VERSION ""

NS_ :

BS_:

BU_: PanelECU
VAL_TABLE_ TransmitError 1 "Error" 0 "Right" ;
VAL_TABLE_ Receive_Error 1 "Error" 0 "Right" ;
VAL_TABLE_ ESD_Error 1 "ESD_Error" 0 "ESD_Right" ;
VAL_TABLE_ SSD_Error 1 "SSD_Error" 0 "SSD_Right" ;
VAL_TABLE_ Master_Slave 1 "Master" 0 "Slave" ;
VAL_TABLE_ Sleep_on_off 1 "Sleep_on" 0 "Sleep_off" ;
VAL_TABLE_ Power_on_off 1 "Power_on" 0 "Power_off" ;
VAL_TABLE_ Link_on_off 1 "Link_on" 0 "Link_off" ;

BO_ 3221225472 VECTOR__INDEPENDENT_SIG_MSG: 0 Vector__XXX
 SG_ CmdPhyValue : 0|8@1- (1,0) [0|0] "" Vector__XXX
 SG_ CmdAddr : 0|8@1- (1,0) [0|0] "" Vector__XXX
 SG_ CmdPhyAdr : 0|8@1- (1,0) [0|0] "" Vector__XXX
 SG_ CmdNumber : 0|8@1- (1,0) [0|0] "" Vector__XXX
 SG_ CmdNumber : 0|8@1- (1,0) [0|0] "" Vector__XXX
 SG_ CmdNumber : 0|8@1- (1,0) [0|0] "" Vector__XXX
 SG_ CmdNumber : 0|8@1- (1,0) [0|0] "" Vector__XXX
 SG_ CmdNumber : 0|8@1- (1,0) [0|0] "" Vector__XXX
 SG_ CmdNumber : 0|8@1- (1,0) [0|0] "" Vector__XXX
 SG_ CmdNumber : 0|8@1- (1,0) [0|0] "" Vector__XXX
 SG_ CmdNumber : 0|8@1- (1,0) [0|0] "" Vector__XXX
 SG_ CmdNumber : 0|8@1- (1,0) [0|0] "" Vector__XXX
 SG_ CRCErrorCount : 0|8@1- (1,0) [0|0] "" Vector__XXX
 SG_ CRCErrorCount : 0|8@1- (1,0) [0|0] "" Vector__XXX

BO_ 1040 LP_COMMAND: 8 PanelECU

BO_ 1024 LP_OPERATOR: 8 PanelECU

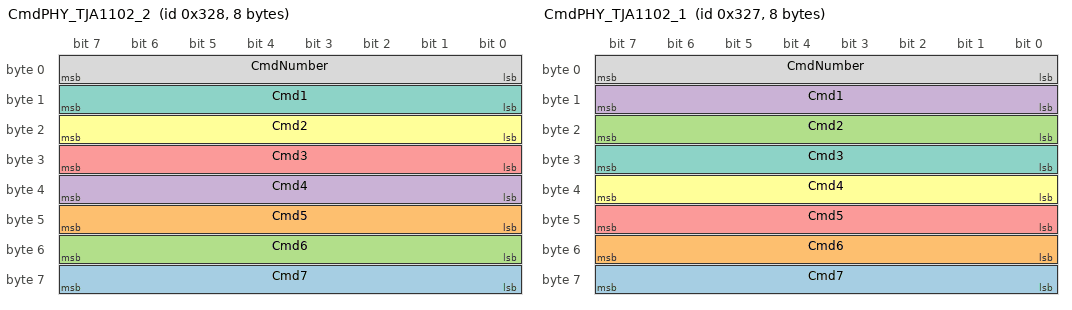
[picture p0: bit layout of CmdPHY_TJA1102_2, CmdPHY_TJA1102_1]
BO_ 808 CmdPHY_TJA1102_2: 8 PanelECU
 SG_ Cmd7 : 56|8@1- (1,0) [0|0] "" Vector__XXX
 SG_ Cmd5 : 40|8@1- (1,0) [0|0] "" Vector__XXX
 SG_ Cmd6 : 48|8@1- (1,0) [0|0] "" Vector__XXX
 SG_ Cmd4 : 32|8@1- (1,0) [0|0] "" Vector__XXX
 SG_ Cmd3 : 24|8@1- (1,0) [0|0] "" Vector__XXX
 SG_ Cmd2 : 16|8@1- (1,0) [0|0] "" Vector__XXX
 SG_ Cmd1 : 8|8@1- (1,0) [0|0] "" Vector__XXX
 SG_ CmdNumber : 0|8@1- (1,0) [0|0] "" Vector__XXX

BO_ 807 CmdPHY_TJA1102_1: 8 PanelECU
 SG_ Cmd7 : 56|8@1- (1,0) [0|0] "" Vector__XXX
 SG_ Cmd6 : 48|8@1- (1,0) [0|0] "" Vector__XXX
 SG_ Cmd2 : 16|8@1- (1,0) [0|0] "" Vector__XXX
 SG_ Cmd1 : 8|8@1- (1,0) [0|0] "" Vector__XXX
 SG_ Cmd5 : 40|8@1- (1,0) [0|0] "" Vector__XXX
 SG_ Cmd4 : 32|8@1- (1,0) [0|0] "" Vector__XXX
 SG_ Cmd3 : 24|8@1- (1,0) [0|0] "" Vector__XXX
 SG_ CmdNumber : 0|8@1- (1,0) [0|0] "" Vector__XXX

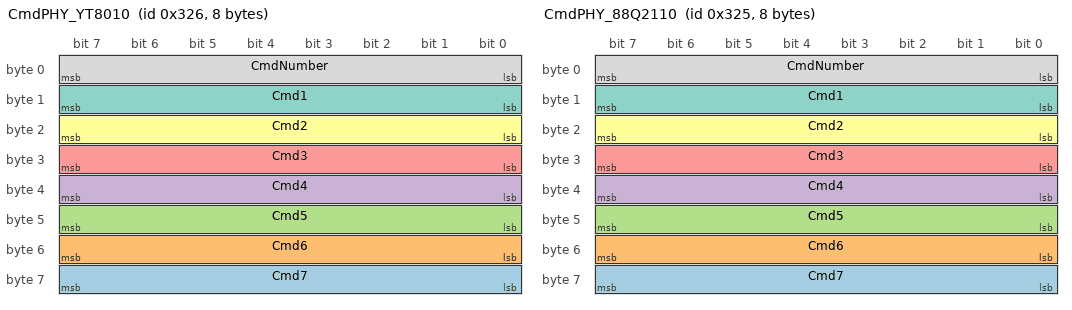
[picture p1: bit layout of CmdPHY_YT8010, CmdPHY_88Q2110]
BO_ 806 CmdPHY_YT8010: 8 PanelECU
 SG_ Cmd7 : 56|8@1- (1,0) [0|0] "" Vector__XXX
 SG_ Cmd6 : 48|8@1- (1,0) [0|0] "" Vector__XXX
 SG_ Cmd5 : 40|8@1- (1,0) [0|0] "" Vector__XXX
 SG_ Cmd4 : 32|8@1- (1,0) [0|0] "" Vector__XXX
 SG_ Cmd3 : 24|8@1- (1,0) [0|0] "" Vector__XXX
 SG_ Cmd2 : 16|8@1- (1,0) [0|0] "" Vector__XXX
 SG_ Cmd1 : 8|8@1- (1,0) [0|0] "" Vector__XXX
 SG_ CmdNumber : 0|8@1- (1,0) [0|0] "" Vector__XXX

BO_ 805 CmdPHY_88Q2110: 8 PanelECU
 SG_ Cmd7 : 56|8@1- (1,0) [0|0] "" Vector__XXX
 SG_ Cmd6 : 48|8@1- (1,0) [0|0] "" Vector__XXX
 SG_ Cmd5 : 40|8@1- (1,0) [0|0] "" Vector__XXX
 SG_ Cmd4 : 32|8@1- (1,0) [0|0] "" Vector__XXX
 SG_ Cmd3 : 24|8@1- (1,0) [0|0] "" Vector__XXX
 SG_ Cmd2 : 16|8@1- (1,0) [0|0] "" Vector__XXX
 SG_ Cmd1 : 8|8@1- (1,0) [0|0] "" Vector__XXX
 SG_ CmdNumber : 0|8@1- (1,0) [0|0] "" Vector__XXX

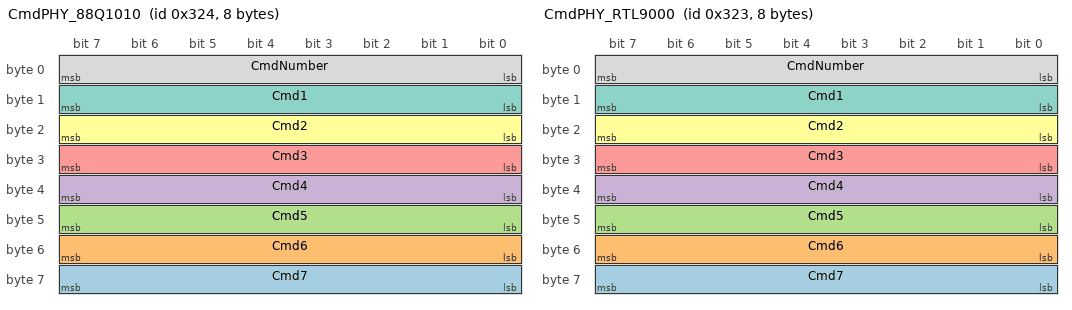
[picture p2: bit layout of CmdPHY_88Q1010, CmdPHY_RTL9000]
BO_ 804 CmdPHY_88Q1010: 8 PanelECU
 SG_ Cmd7 : 56|8@1- (1,0) [0|0] "" Vector__XXX
 SG_ Cmd6 : 48|8@1- (1,0) [0|0] "" Vector__XXX
 SG_ Cmd5 : 40|8@1- (1,0) [0|0] "" Vector__XXX
 SG_ Cmd4 : 32|8@1- (1,0) [0|0] "" Vector__XXX
 SG_ Cmd3 : 24|8@1- (1,0) [0|0] "" Vector__XXX
 SG_ Cmd2 : 16|8@1- (1,0) [0|0] "" Vector__XXX
 SG_ Cmd1 : 8|8@1- (1,0) [0|0] "" Vector__XXX
 SG_ CmdNumber : 0|8@1- (1,0) [0|0] "" Vector__XXX

BO_ 803 CmdPHY_RTL9000: 8 PanelECU
 SG_ Cmd7 : 56|8@1- (1,0) [0|0] "" Vector__XXX
 SG_ Cmd6 : 48|8@1- (1,0) [0|0] "" Vector__XXX
 SG_ Cmd5 : 40|8@1- (1,0) [0|0] "" Vector__XXX
 SG_ Cmd4 : 32|8@1- (1,0) [0|0] "" Vector__XXX
 SG_ Cmd3 : 24|8@1- (1,0) [0|0] "" Vector__XXX
 SG_ Cmd2 : 16|8@1- (1,0) [0|0] "" Vector__XXX
 SG_ Cmd1 : 8|8@1- (1,0) [0|0] "" Vector__XXX
 SG_ CmdNumber : 0|8@1- (1,0) [0|0] "" Vector__XXX

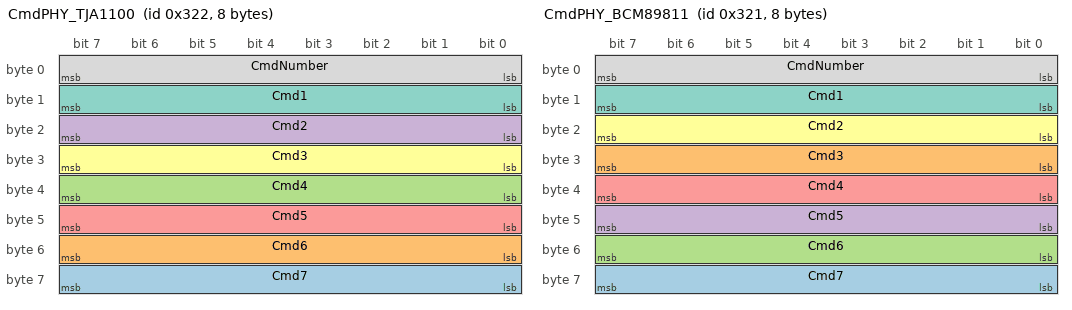
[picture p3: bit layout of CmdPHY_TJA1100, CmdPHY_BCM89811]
BO_ 802 CmdPHY_TJA1100: 8 PanelECU
 SG_ Cmd7 : 56|8@1- (1,0) [0|0] "" Vector__XXX
 SG_ Cmd6 : 48|8@1- (1,0) [0|0] "" Vector__XXX
 SG_ Cmd4 : 32|8@1- (1,0) [0|0] "" Vector__XXX
 SG_ Cmd2 : 16|8@1- (1,0) [0|0] "" Vector__XXX
 SG_ Cmd5 : 40|8@1- (1,0) [0|0] "" Vector__XXX
 SG_ Cmd3 : 24|8@1- (1,0) [0|0] "" Vector__XXX
 SG_ Cmd1 : 8|8@1- (1,0) [0|0] "" Vector__XXX
 SG_ CmdNumber : 0|8@1- (1,0) [0|0] "" Vector__XXX

BO_ 801 CmdPHY_BCM89811: 8 PanelECU
 SG_ Cmd7 : 56|8@1- (1,0) [0|0] "" Vector__XXX
 SG_ Cmd3 : 24|8@1- (1,0) [0|0] "" Vector__XXX
 SG_ Cmd6 : 48|8@1- (1,0) [0|0] "" Vector__XXX
 SG_ Cmd5 : 40|8@1- (1,0) [0|0] "" Vector__XXX
 SG_ Cmd4 : 32|8@1- (1,0) [0|0] "" Vector__XXX
 SG_ Cmd2 : 16|8@1- (1,0) [0|0] "" Vector__XXX
 SG_ Cmd1 : 8|8@1- (1,0) [0|0] "" Vector__XXX
 SG_ CmdNumber : 0|8@1- (1,0) [0|0] "" Vector__XXX

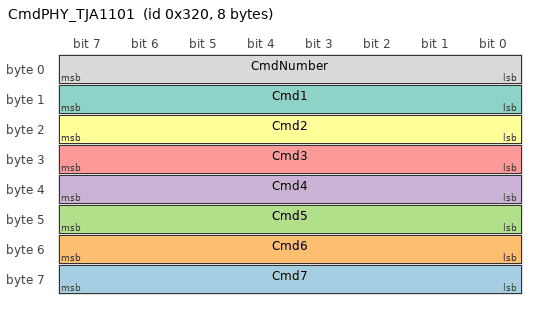
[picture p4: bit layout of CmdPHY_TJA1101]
BO_ 800 CmdPHY_TJA1101: 8 PanelECU
 SG_ Cmd7 : 56|8@1- (1,0) [0|0] "" Vector__XXX
 SG_ Cmd6 : 48|8@1- (1,0) [0|0] "" Vector__XXX
 SG_ Cmd5 : 40|8@1- (1,0) [0|0] "" Vector__XXX
 SG_ Cmd4 : 32|8@1- (1,0) [0|0] "" Vector__XXX
 SG_ Cmd3 : 24|8@1- (1,0) [0|0] "" Vector__XXX
 SG_ Cmd2 : 16|8@1- (1,0) [0|0] "" Vector__XXX
 SG_ Cmd1 : 8|8@1- (1,0) [0|0] "" Vector__XXX
 SG_ CmdNumber : 0|8@1- (1,0) [0|0] "" Vector__XXX

EV_ EnvError: 0 [0|0] "" 0 1 DUMMY_NODE_VECTOR0 Vector__XXX;

EV_ EnvRecvLoss: 0 [0|2147483647] "" 0 2 DUMMY_NODE_VECTOR0 Vector__XXX;

EV_ EnvRecvCntErr: 0 [0|0] "" 0 3 DUMMY_NODE_VECTOR0 Vector__XXX;

EV_ EnvCRCError: 0 [0|0] "" 0 4 DUMMY_NODE_VECTOR0 Vector__XXX;

EV_ EnvLatestWkptick: 0 [0|268435455] "" 0 5 DUMMY_NODE_VECTOR0 Vector__XXX;

EV_ EnvReceiveStatus: 0 [0|0] "" 0 6 DUMMY_NODE_VECTOR0 Vector__XXX;

EV_ EnvTransmitStatus: 0 [0|0] "" 0 7 DUMMY_NODE_VECTOR0 Vector__XXX;

EV_ EnvLatestSlptick: 0 [0|268435455] "" 0 8 DUMMY_NODE_VECTOR0 Vector__XXX;

EV_ EnvWakeup: 0 [0|0] "" 0 9 DUMMY_NODE_VECTOR0 Vector__XXX;

EV_ EnvLinkError: 0 [0|0] "" 0 10 DUMMY_NODE_VECTOR0 Vector__XXX;

EV_ EnvDttError: 0 [0|0] "" 0 11 DUMMY_NODE_VECTOR0 Vector__XXX;

EV_ EnvSQI: 0 [0|15] "" 0 12 DUMMY_NODE_VECTOR0 Vector__XXX;

EV_ EnvReceiveError: 0 [0|0] "" 0 13 DUMMY_NODE_VECTOR0 Vector__XXX;

EV_ EnvSleepOnOff: 0 [0|0] "" 0 14 DUMMY_NODE_VECTOR0 Vector__XXX;

EV_ EnvTestMode: 0 [0|15] "" 0 15 DUMMY_NODE_VECTOR0 Vector__XXX;

EV_ EnvTransmitError: 0 [0|0] "" 0 16 DUMMY_NODE_VECTOR0 Vector__XXX;

EV_ EnvSsdError: 0 [0|0] "" 0 17 DUMMY_NODE_VECTOR0 Vector__XXX;

EV_ EnvRemoteErrCnt: 0 [0|255] "" 0 18 DUMMY_NODE_VECTOR0 Vector__XXX;

EV_ EnvReceiveErrCnt: 0 [0|255] "" 0 19 DUMMY_NODE_VECTOR0 Vector__XXX;

EV_ EnvPowerOnOff: 0 [0|0] "" 0 20 DUMMY_NODE_VECTOR0 Vector__XXX;

EV_ EnvMasterSlave: 0 [0|0] "" 0 21 DUMMY_NODE_VECTOR0 Vector__XXX;

EV_ EnvLinkOnOff: 0 [0|0] "" 0 22 DUMMY_NODE_VECTOR0 Vector__XXX;

EV_ EnvEsdError: 0 [0|0] "" 0 23 DUMMY_NODE_VECTOR0 Vector__XXX;

EV_ EnvCRCErrorCount: 0 [0|255] "" 0 24 DUMMY_NODE_VECTOR0 Vector__XXX;

CM_ BO_ 3221225472 "This is a message for not used signals, created by Vector CANdb++ DBC OLE DB Provider.";
BA_DEF_  "BusType" STRING ;
BA_DEF_DEF_  "BusType" "CAN";
